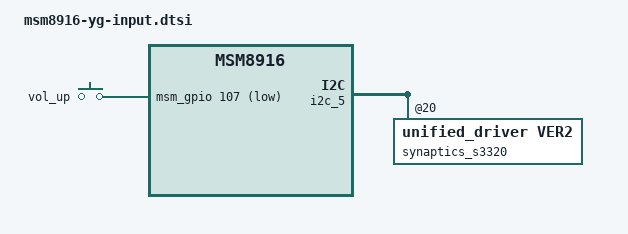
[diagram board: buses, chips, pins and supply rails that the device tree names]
/* Copyright (c) 2012, Code Aurora Forum. All rights reserved.
 *
 * This program is free software; you can redistribute it and/or modify
 * it under the terms of the GNU General Public License version 2 and
 * only version 2 as published by the Free Software Foundation.
 *
 * This program is distributed in the hope that it will be useful,
 * but WITHOUT ANY WARRANTY; without even the implied warranty of
 * MERCHANTABILITY or FITNESS FOR A PARTICULAR PURPOSE.  See the
 * GNU General Public License for more details.
 */

&i2c_5 {
	qcom,clk-freq-out = <400000>;

	synaptics_s3320@20 {
		compatible = "unified_driver,ver2";
		status = "ok";
		revision = "rev_0...";

		fw_image = "synaptics/yg/PLG521-V1.05-PR1880096-DS5.2.12.1013_40050185.img";
		panel_spec = "synaptics/yg/limit.txt";
		pinctrl-names = "default","sleep"; 				/*Touch GPIO pin name setting*/
		pinctrl-0 = <&ts_int_active &ts_reset_active>;                  /*Touch GPIO pin active setting*/
		pinctrl-1 = <&ts_int_suspend &ts_reset_suspend>;                /*Touch GPIO pin suspend setting*/
	};
};

&soc {
	gpio_keys {
		vol_up {
			gpios = <&msm_gpio 107 0x1>;
		};
		vol_down {
			status = "disabled";
			/delete-property/ debounce-interval;
			/delete-property/ gpio-key,wakeup;
			/delete-property/ gpios;
			/delete-property/ label;
			/delete-property/ linux,code;
			/delete-property/ linux,input-type;
		};
	};
};
